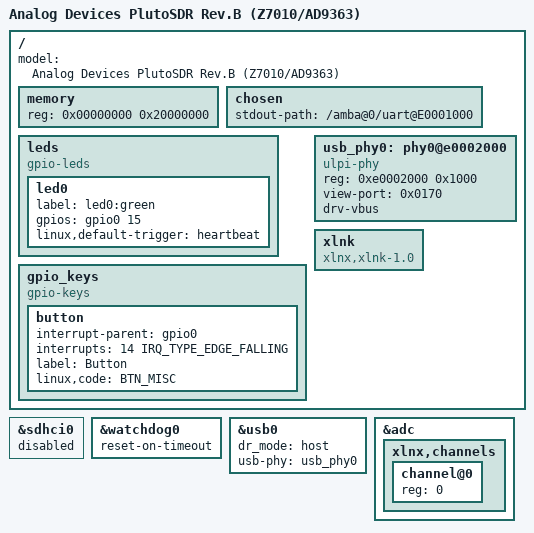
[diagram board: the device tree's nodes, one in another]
/include/ "system-conf.dtsi"

#include "zynq.dtsi"
#include <dt-bindings/input/input.h>
#include <dt-bindings/gpio/gpio.h>
#include <dt-bindings/interrupt-controller/irq.h>

/ {
    model = "Analog Devices PlutoSDR Rev.B (Z7010/AD9363)";

    memory {
		device_type = "memory";
		reg = <0x00000000 0x20000000>;
	};

	chosen {
		stdout-path = "/amba@0/uart@E0001000";
	};

    leds {
		compatible = "gpio-leds";
		led0 {
			label = "led0:green";
			gpios = <&gpio0 15 0>;
			linux,default-trigger = "heartbeat";
		};
	};

	gpio_keys {
		compatible = "gpio-keys";
		#address-cells = <1>;
		#size-cells = <0>;

		button {
			interrupt-parent = <&gpio0>;
			interrupts = <14 IRQ_TYPE_EDGE_FALLING>;
			label = "Button";
			linux,code = <BTN_MISC>;
		};

	};

    usb_phy0: phy0@e0002000 {
        compatible = "ulpi-phy";
        #phy-cells = <0>;
        reg = <0xe0002000 0x1000>;
        view-port = <0x0170>;
        drv-vbus;
    };

    xlnk {
		compatible = "xlnx,xlnk-1.0";
	};
};

&sdhci0 {
	status = "disabled";
};

&watchdog0 {
	status = "okay";
	reset-on-timeout;
};

&usb0 {
    dr_mode = "host";
    usb-phy = <&usb_phy0>;
    status = "okay";
};

&adc {
	xlnx,channels {
		#address-cells = <1>;
		#size-cells = <0>;
		channel@0 {
			reg = <0>;
		};
	};
};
